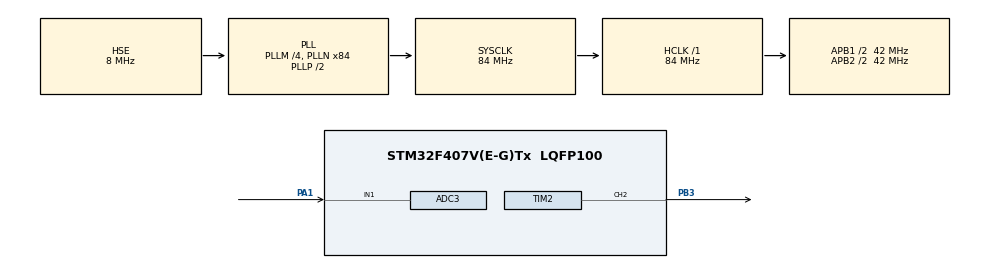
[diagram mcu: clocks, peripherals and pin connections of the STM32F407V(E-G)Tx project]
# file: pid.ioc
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ADC3.Channel-0\#ChannelRegularConversion=ADC_CHANNEL_1
ADC3.NbrOfConversionFlag=1
ADC3.Rank-0\#ChannelRegularConversion=1
ADC3.SamplingTime-0\#ChannelRegularConversion=ADC_SAMPLETIME_480CYCLES
Mcu.Family=STM32F4
Mcu.Name=STM32F407V(E-G)Tx
Mcu.Package=LQFP100
NVIC.PriorityGroup=NVIC_PRIORITYGROUP_0
NVIC.TIM2_IRQn=true\:0\:0\:false\:false\:true\:true\:true\:true
NVIC.TIM3_IRQn=true\:0\:0\:false\:false\:true\:true\:true\:true
PA1.Signal=ADCx_IN1
PB3.Signal=S_TIM2_CH2
PH0-OSC_IN.Mode=HSE-External-Oscillator
PH0-OSC_IN.Signal=RCC_OSC_IN
PH1-OSC_OUT.Mode=HSE-External-Oscillator
PH1-OSC_OUT.Signal=RCC_OSC_OUT
ProjectManager.HeapSize=0x200
ProjectManager.StackSize=0x400
ProjectManager.TargetToolchain=STM32CubeIDE
RCC.48MHZClocksFreq_Value=24000000
RCC.AHBFreq_Value=84000000
RCC.APB1CLKDivider=RCC_HCLK_DIV2
RCC.APB1Freq_Value=42000000
RCC.APB1TimFreq_Value=84000000
RCC.APB2CLKDivider=RCC_HCLK_DIV2
RCC.APB2Freq_Value=42000000
RCC.APB2TimFreq_Value=84000000
RCC.CortexFreq_Value=84000000
RCC.HCLKFreq_Value=84000000
RCC.HSE_VALUE=8000000
RCC.HSI_VALUE=16000000
RCC.PLLM=4
RCC.PLLN=84
RCC.PLLQ=7
RCC.PLLSourceVirtual=RCC_PLLSOURCE_HSE
RCC.SYSCLKFreq_VALUE=84000000
RCC.SYSCLKSource=RCC_SYSCLKSOURCE_PLLCLK
RCC.VCOOutputFreq_Value=168000000
SH.ADCx_IN1.0=ADC3_IN1,IN1
SH.S_TIM2_CH2.0=TIM2_CH2,PWM Generation2 CH2
TIM2.Channel-PWM\ Generation2\ CH2=TIM_CHANNEL_2
TIM2.Period=1000-1
TIM2.Prescaler=84-1
TIM3.Period=999
TIM3.Prescaler=83
VP_TIM3_VS_ClockSourceINT.Mode=Internal
board=STM32F407G-DISC1

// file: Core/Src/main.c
/* USER CODE BEGIN Header */
/**
  ******************************************************************************
  * @file           : main.c
  * @brief          : Main program body
  ******************************************************************************
  * @attention
  *
  * Copyright (c) 2024 STMicroelectronics.
  * All rights reserved.
  *
  * This software is licensed under terms that can be found in the LICENSE file
  * in the root directory of this software component.
  * If no LICENSE file comes with this software, it is provided AS-IS.
  *
  ******************************************************************************
  */
/* USER CODE END Header */
#include "main.h"

ADC_HandleTypeDef hadc3;

TIM_HandleTypeDef htim2;
TIM_HandleTypeDef htim3;

/* USER CODE BEGIN PV */

float Kp = 1.0f;
float Ki = 0.18f;
float Kd = 0.001f;

float setpoint = 500.0f; // Hedef RPM
float integral = 0.0f;
float previous_error = 0.0f;
float get_ADC=0;
float error=0;
int output=0;
float derivative=0;
float rpm=200;

/* USER CODE END PV */

void SystemClock_Config(void);
static void MX_GPIO_Init(void);
static void MX_TIM2_Init(void);
static void MX_TIM3_Init(void);
static void MX_ADC3_Init(void);

/* USER CODE BEGIN 0 */
uint32_t Read_ADC(void) {
    HAL_ADC_Start(&hadc3);
    HAL_ADC_PollForConversion(&hadc3, HAL_MAX_DELAY);
    get_ADC=HAL_ADC_GetValue(&hadc3);
    return get_ADC;
}
float Calculate_RPM(uint32_t adc_value) {

	HAL_Delay(200);
	rpm=rpm+10;
	    return rpm;

	}
void PID_Control(void) {
     uint32_t adc_value = Read_ADC();
     float rpm = Calculate_RPM(adc_value);
     float error = setpoint - rpm;
     integral += error;
     derivative = error - previous_error;
     output = Kp * error + Ki * integral + Kd * derivative;
     previous_error = error;
     if (output>1000){
     	output=1000;
     	}
     if(output<50){
         		output=50;
     }

     // PWM çıkışını ayarla
     __HAL_TIM_SET_COMPARE(&htim2, TIM_CHANNEL_2, (int)output);
 }

/* USER CODE END 0 */

int main(void)
{

  /* MCU Configuration--------------------------------------------------------*/

  /* Reset of all peripherals, Initializes the Flash interface and the Systick. */
   HAL_Init();

  /* Configure the system clock */
  SystemClock_Config();

  /* Initialize all configured peripherals */
  MX_GPIO_Init();
  MX_TIM2_Init();
  MX_TIM3_Init();
  MX_ADC3_Init();
  /* USER CODE BEGIN 2 */

  HAL_TIM_PWM_Start(&htim2, TIM_CHANNEL_2); // PWM çıkışını başlat
  HAL_TIM_Base_Start_IT(&htim3); // Timer3'ü başlat (interrupt ile)

  /* USER CODE END 2 */

  /* Infinite loop */
  while (1)
  {
PID_Control();
HAL_Delay(100);
  }
}

void SystemClock_Config(void)
{
  RCC_OscInitTypeDef RCC_OscInitStruct = {0};
  RCC_ClkInitTypeDef RCC_ClkInitStruct = {0};

  /** Configure the main internal regulator output voltage
  */
  __HAL_RCC_PWR_CLK_ENABLE();
  __HAL_PWR_VOLTAGESCALING_CONFIG(PWR_REGULATOR_VOLTAGE_SCALE1);

  /** Initializes the RCC Oscillators according to the specified parameters
  * in the RCC_OscInitTypeDef structure.
  */
  RCC_OscInitStruct.OscillatorType = RCC_OSCILLATORTYPE_HSE;
  RCC_OscInitStruct.HSEState = RCC_HSE_ON;
  RCC_OscInitStruct.PLL.PLLState = RCC_PLL_ON;
  RCC_OscInitStruct.PLL.PLLSource = RCC_PLLSOURCE_HSE;
  RCC_OscInitStruct.PLL.PLLM = 4;
  RCC_OscInitStruct.PLL.PLLN = 84;
  RCC_OscInitStruct.PLL.PLLP = RCC_PLLP_DIV2;
  RCC_OscInitStruct.PLL.PLLQ = 7;
  if (HAL_RCC_OscConfig(&RCC_OscInitStruct) != HAL_OK)
  {
    Error_Handler();
  }

  /** Initializes the CPU, AHB and APB buses clocks
  */
  RCC_ClkInitStruct.ClockType = RCC_CLOCKTYPE_HCLK|RCC_CLOCKTYPE_SYSCLK
                              |RCC_CLOCKTYPE_PCLK1|RCC_CLOCKTYPE_PCLK2;
  RCC_ClkInitStruct.SYSCLKSource = RCC_SYSCLKSOURCE_PLLCLK;
  RCC_ClkInitStruct.AHBCLKDivider = RCC_SYSCLK_DIV1;
  RCC_ClkInitStruct.APB1CLKDivider = RCC_HCLK_DIV2;
  RCC_ClkInitStruct.APB2CLKDivider = RCC_HCLK_DIV2;

  if (HAL_RCC_ClockConfig(&RCC_ClkInitStruct, FLASH_LATENCY_2) != HAL_OK)
  {
    Error_Handler();
  }
}

static void MX_ADC3_Init(void)
{

  ADC_ChannelConfTypeDef sConfig = {0};

  /** Configure the global features of the ADC (Clock, Resolution, Data Alignment and number of conversion)
  */
  hadc3.Instance = ADC3;
  hadc3.Init.ClockPrescaler = ADC_CLOCK_SYNC_PCLK_DIV2;
  hadc3.Init.Resolution = ADC_RESOLUTION_12B;
  hadc3.Init.ScanConvMode = DISABLE;
  hadc3.Init.ContinuousConvMode = DISABLE;
  hadc3.Init.DiscontinuousConvMode = DISABLE;
  hadc3.Init.ExternalTrigConvEdge = ADC_EXTERNALTRIGCONVEDGE_NONE;
  hadc3.Init.ExternalTrigConv = ADC_SOFTWARE_START;
  hadc3.Init.DataAlign = ADC_DATAALIGN_RIGHT;
  hadc3.Init.NbrOfConversion = 1;
  hadc3.Init.DMAContinuousRequests = DISABLE;
  hadc3.Init.EOCSelection = ADC_EOC_SINGLE_CONV;
  if (HAL_ADC_Init(&hadc3) != HAL_OK)
  {
    Error_Handler();
  }

  /** Configure for the selected ADC regular channel its corresponding rank in the sequencer and its sample time.
  */
  sConfig.Channel = ADC_CHANNEL_1;
  sConfig.Rank = 1;
  sConfig.SamplingTime = ADC_SAMPLETIME_480CYCLES;
  if (HAL_ADC_ConfigChannel(&hadc3, &sConfig) != HAL_OK)
  {
    Error_Handler();
  }

}

static void MX_TIM2_Init(void)
{

  TIM_MasterConfigTypeDef sMasterConfig = {0};
  TIM_OC_InitTypeDef sConfigOC = {0};

  htim2.Instance = TIM2;
  htim2.Init.Prescaler = 84-1;
  htim2.Init.CounterMode = TIM_COUNTERMODE_UP;
  htim2.Init.Period = 1000-1;
  htim2.Init.ClockDivision = TIM_CLOCKDIVISION_DIV1;
  htim2.Init.AutoReloadPreload = TIM_AUTORELOAD_PRELOAD_DISABLE;
  if (HAL_TIM_PWM_Init(&htim2) != HAL_OK)
  {
    Error_Handler();
  }
  sMasterConfig.MasterOutputTrigger = TIM_TRGO_RESET;
  sMasterConfig.MasterSlaveMode = TIM_MASTERSLAVEMODE_DISABLE;
  if (HAL_TIMEx_MasterConfigSynchronization(&htim2, &sMasterConfig) != HAL_OK)
  {
    Error_Handler();
  }
  sConfigOC.OCMode = TIM_OCMODE_PWM1;
  sConfigOC.Pulse = 0;
  sConfigOC.OCPolarity = TIM_OCPOLARITY_HIGH;
  sConfigOC.OCFastMode = TIM_OCFAST_DISABLE;
  if (HAL_TIM_PWM_ConfigChannel(&htim2, &sConfigOC, TIM_CHANNEL_2) != HAL_OK)
  {
    Error_Handler();
  }
  HAL_TIM_MspPostInit(&htim2);

}

static void MX_TIM3_Init(void)
{

  TIM_ClockConfigTypeDef sClockSourceConfig = {0};
  TIM_MasterConfigTypeDef sMasterConfig = {0};

  htim3.Instance = TIM3;
  htim3.Init.Prescaler = 83;
  htim3.Init.CounterMode = TIM_COUNTERMODE_UP;
  htim3.Init.Period = 999;
  htim3.Init.ClockDivision = TIM_CLOCKDIVISION_DIV1;
  htim3.Init.AutoReloadPreload = TIM_AUTORELOAD_PRELOAD_DISABLE;
  if (HAL_TIM_Base_Init(&htim3) != HAL_OK)
  {
    Error_Handler();
  }
  sClockSourceConfig.ClockSource = TIM_CLOCKSOURCE_INTERNAL;
  if (HAL_TIM_ConfigClockSource(&htim3, &sClockSourceConfig) != HAL_OK)
  {
    Error_Handler();
  }
  sMasterConfig.MasterOutputTrigger = TIM_TRGO_RESET;
  sMasterConfig.MasterSlaveMode = TIM_MASTERSLAVEMODE_DISABLE;
  if (HAL_TIMEx_MasterConfigSynchronization(&htim3, &sMasterConfig) != HAL_OK)
  {
    Error_Handler();
  }

}

static void MX_GPIO_Init(void)
{

  /* GPIO Ports Clock Enable */
  __HAL_RCC_GPIOH_CLK_ENABLE();
  __HAL_RCC_GPIOA_CLK_ENABLE();
  __HAL_RCC_GPIOB_CLK_ENABLE();

}

void Error_Handler(void)
{
  __disable_irq();
  while (1)
  {
  }
}
